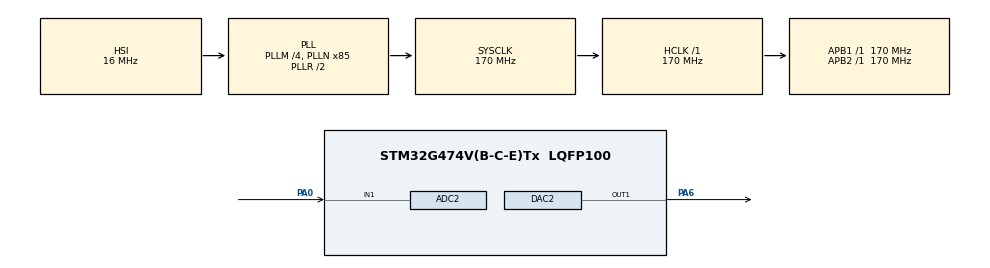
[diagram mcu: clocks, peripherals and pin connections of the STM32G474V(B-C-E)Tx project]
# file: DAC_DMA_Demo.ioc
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ADC2.Channel-0\#ChannelRegularConversion=ADC_CHANNEL_1
ADC2.ExternalTrigConv=ADC_EXTERNALTRIG_T6_TRGO
ADC2.NbrOfConversionFlag=1
ADC2.OffsetNumber-0\#ChannelRegularConversion=ADC_OFFSET_NONE
ADC2.Rank-0\#ChannelRegularConversion=1
ADC2.SamplingTime-0\#ChannelRegularConversion=ADC_SAMPLETIME_2CYCLES_5
DAC2.DAC_Trigger_OUT1-DAC_OUT1=DAC_TRIGGER_T6_TRGO
Dma.DAC2_CH1.0.Direction=DMA_MEMORY_TO_PERIPH
Dma.DAC2_CH1.0.EventEnable=DISABLE
Dma.DAC2_CH1.0.Instance=DMA1_Channel1
Dma.DAC2_CH1.0.MemDataAlignment=DMA_MDATAALIGN_HALFWORD
Dma.DAC2_CH1.0.MemInc=DMA_MINC_ENABLE
Dma.DAC2_CH1.0.Mode=DMA_CIRCULAR
Dma.DAC2_CH1.0.PeriphDataAlignment=DMA_PDATAALIGN_WORD
Dma.DAC2_CH1.0.PeriphInc=DMA_PINC_DISABLE
Dma.DAC2_CH1.0.Polarity=HAL_DMAMUX_REQ_GEN_RISING
Dma.DAC2_CH1.0.Priority=DMA_PRIORITY_LOW
Dma.DAC2_CH1.0.RequestNumber=1
Dma.DAC2_CH1.0.SignalID=NONE
Dma.DAC2_CH1.0.SyncEnable=DISABLE
Dma.DAC2_CH1.0.SyncPolarity=HAL_DMAMUX_SYNC_NO_EVENT
Dma.DAC2_CH1.0.SyncRequestNumber=1
Dma.DAC2_CH1.0.SyncSignalID=NONE
Dma.Request0=DAC2_CH1
Mcu.Family=STM32G4
Mcu.Name=STM32G474V(B-C-E)Tx
Mcu.Package=LQFP100
NVIC.DMA1_Channel1_IRQn=true\:0\:0\:false\:false\:true\:false\:true\:true
NVIC.PriorityGroup=NVIC_PRIORITYGROUP_4
PA0.Mode=IN1-Single-Ended
PA0.Signal=ADC2_IN1
PA13.Mode=Serial_Wire
PA13.Signal=SYS_JTMS-SWDIO
PA14.Mode=Serial_Wire
PA14.Signal=SYS_JTCK-SWCLK
PA6.Signal=COMP_DAC21_group
PC14-OSC32_IN.Mode=LSE-External-Oscillator
PC14-OSC32_IN.Signal=RCC_OSC32_IN
PC15-OSC32_OUT.Mode=LSE-External-Oscillator
PC15-OSC32_OUT.Signal=RCC_OSC32_OUT
PF0-OSC_IN.Mode=HSE-External-Oscillator
PF0-OSC_IN.Signal=RCC_OSC_IN
PF1-OSC_OUT.Mode=HSE-External-Oscillator
PF1-OSC_OUT.Signal=RCC_OSC_OUT
ProjectManager.HeapSize=0x200
ProjectManager.StackSize=0x400
ProjectManager.TargetToolchain=MDK-ARM V5.32
RCC.ADC12Freq_Value=170000000
RCC.ADC345Freq_Value=170000000
RCC.AHBFreq_Value=170000000
RCC.APB1Freq_Value=170000000
RCC.APB1TimFreq_Value=170000000
RCC.APB2Freq_Value=170000000
RCC.APB2TimFreq_Value=170000000
RCC.CortexFreq_Value=170000000
RCC.EXTERNAL_CLOCK_VALUE=12288000
RCC.HCLKFreq_Value=170000000
RCC.HSE_VALUE=8000000
RCC.HSI48_VALUE=48000000
RCC.HSI_VALUE=16000000
RCC.PLLM=RCC_PLLM_DIV4
RCC.PLLN=85
RCC.SYSCLKFreq_VALUE=170000000
RCC.SYSCLKSource=RCC_SYSCLKSOURCE_PLLCLK
RCC.USBFreq_Value=170000000
RCC.VCOOutputFreq_Value=340000000
SH.COMP_DAC21_group.0=DAC2_OUT1,DAC_OUT1
TIM6.AutoReloadPreload=TIM_AUTORELOAD_PRELOAD_ENABLE
TIM6.PeriodNoDither=10000-1
TIM6.TIM_MasterOutputTrigger=TIM_TRGO_UPDATE
VP_SYS_VS_DBSignals.Mode=DisableDeadBatterySignals
VP_TIM6_VS_ClockSourceINT.Mode=Enable_Timer
board=custom

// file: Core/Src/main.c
/* USER CODE BEGIN Header */
/**
  ******************************************************************************
  * @file           : main.c
  * @brief          : Main program body
  ******************************************************************************
  * @attention
  *
  * Copyright (c) 2025 STMicroelectronics.
  * All rights reserved.
  *
  * This software is licensed under terms that can be found in the LICENSE file
  * in the root directory of this software component.
  * If no LICENSE file comes with this software, it is provided AS-IS.
  *
  ******************************************************************************
  */
/* USER CODE END Header */
#include "main.h"
#include "adc.h"
#include "dac.h"
#include "dma.h"
#include "tim.h"
#include "gpio.h"

void SystemClock_Config(void);

/* USER CODE BEGIN 0 */

uint16_t sin_data[340] = {
	2066,2104,2142,2179,2217,2255,2292,2330,2367,2405,2442,2479,2516,2552,2589,2625,2662,
2698,2733,2769,2804,2839,2874,2908,2942,2976,3010,3043,3076,3108,3141,3172,3204,
3235,3265,3296,3325,3355,3384,3412,3440,3467,3494,3521,3547,3572,3597,3622,3646,
3669,3692,3714,3736,3757,3777,3797,3817,3835,3853,3871,3888,3904,3920,3935,3949,
3963,3976,3988,4000,4011,4021,4031,4040,4048,4056,4063,4069,4074,4079,4083,4087,
4090,4092,4093,4094,4094,4093,4092,4090,4087,4083,4079,4074,4069,4063,4056,4048,
4040,4031,4021,4011,4000,3988,3976,3963,3949,3935,3920,3904,3888,3871,3853,3835,
3817,3797,3777,3757,3736,3714,3692,3669,3646,3622,3597,3572,3547,3521,3494,3467,
3440,3412,3384,3355,3325,3296,3265,3235,3204,3172,3141,3108,3076,3043,3010,2976,
2942,2908,2874,2839,2804,2769,2733,2698,2662,2625,2589,2552,2516,2479,2442,2405,
2367,2330,2292,2255,2217,2179,2142,2104,2066,2028,1990,1952,1915,1877,1839,1802,
1764,1727,1689,1652,1615,1578,1542,1505,1469,1432,1396,1361,1325,1290,1255,1220,
1186,1152,1118,1084,1051,1018,986,953,922,890,859,829,798,769,739,710,
682,654,627,600,573,547,522,497,472,448,425,402,380,358,337,317,
297,277,259,241,223,206,190,174,159,145,131,118,106,94,83,73,
63,54,46,38,31,25,20,15,11,7,4,2,1,0,0,1,
2,4,7,11,15,20,25,31,38,46,54,63,73,83,94,106,
118,131,145,159,174,190,206,223,241,259,277,297,317,337,358,380,
402,425,448,472,497,522,547,573,600,627,654,682,710,739,769,798,
829,859,890,922,953,986,1018,1051,1084,1118,1152,1186,1220,1255,1290,1325,
1361,1396,1432,1469,1505,1542,1578,1615,1652,1689,1727,1764,1802,1839,1877,1915,
1952,1990,2028};

/* USER CODE END 0 */

int main(void)
{

  /* MCU Configuration--------------------------------------------------------*/

  /* Reset of all peripherals, Initializes the Flash interface and the Systick. */
  HAL_Init();

  /* Configure the system clock */
  SystemClock_Config();

  /* Initialize all configured peripherals */
  MX_GPIO_Init();
  MX_DMA_Init();
  MX_ADC2_Init();
  MX_DAC2_Init();
  MX_TIM6_Init();
  /* USER CODE BEGIN 2 */

	HAL_TIM_Base_Start(&htim6);
	HAL_DAC_Start_DMA(&hdac2,DAC2_CHANNEL_1,(uint32_t*)sin_data,340,DAC_ALIGN_12B_R);

  /* USER CODE END 2 */

  /* Infinite loop */
  while (1)
  {

  }
}

void SystemClock_Config(void)
{
  RCC_OscInitTypeDef RCC_OscInitStruct = {0};
  RCC_ClkInitTypeDef RCC_ClkInitStruct = {0};

  /** Configure the main internal regulator output voltage
  */
  HAL_PWREx_ControlVoltageScaling(PWR_REGULATOR_VOLTAGE_SCALE1_BOOST);

  /** Initializes the RCC Oscillators according to the specified parameters
  * in the RCC_OscInitTypeDef structure.
  */
  RCC_OscInitStruct.OscillatorType = RCC_OSCILLATORTYPE_HSI;
  RCC_OscInitStruct.HSIState = RCC_HSI_ON;
  RCC_OscInitStruct.HSICalibrationValue = RCC_HSICALIBRATION_DEFAULT;
  RCC_OscInitStruct.PLL.PLLState = RCC_PLL_ON;
  RCC_OscInitStruct.PLL.PLLSource = RCC_PLLSOURCE_HSI;
  RCC_OscInitStruct.PLL.PLLM = RCC_PLLM_DIV4;
  RCC_OscInitStruct.PLL.PLLN = 85;
  RCC_OscInitStruct.PLL.PLLP = RCC_PLLP_DIV2;
  RCC_OscInitStruct.PLL.PLLQ = RCC_PLLQ_DIV2;
  RCC_OscInitStruct.PLL.PLLR = RCC_PLLR_DIV2;
  if (HAL_RCC_OscConfig(&RCC_OscInitStruct) != HAL_OK)
  {
    Error_Handler();
  }

  /** Initializes the CPU, AHB and APB buses clocks
  */
  RCC_ClkInitStruct.ClockType = RCC_CLOCKTYPE_HCLK|RCC_CLOCKTYPE_SYSCLK
                              |RCC_CLOCKTYPE_PCLK1|RCC_CLOCKTYPE_PCLK2;
  RCC_ClkInitStruct.SYSCLKSource = RCC_SYSCLKSOURCE_PLLCLK;
  RCC_ClkInitStruct.AHBCLKDivider = RCC_SYSCLK_DIV1;
  RCC_ClkInitStruct.APB1CLKDivider = RCC_HCLK_DIV1;
  RCC_ClkInitStruct.APB2CLKDivider = RCC_HCLK_DIV1;

  if (HAL_RCC_ClockConfig(&RCC_ClkInitStruct, FLASH_LATENCY_4) != HAL_OK)
  {
    Error_Handler();
  }
}

void Error_Handler(void)
{
  __disable_irq();
  while (1)
  {
  }
}
